# AM13E23019 register map
Vendor: Texas Instruments; File version: 1.0
CPU: CM33 r0p1, little endian, MPU, FPU, VTOR, 4 interrupt priority bits
Registers are 32-bit, read-write, reset 0x0 unless marked. A register's access mark holds for its fields unless they carry their own. Offsets are from the block's base; [hi:lo] are bit positions; {n}, {i} and the like mark numbered series; 'fields as' and 'values as' point back to an identical list.

## ADC0RESULT — ADC_RESULT module
Base 0x4000A000
Same registers: ADC1RESULT 0x4000B000, ADC2RESULT 0x4000C000
{0x0+2i} ADCRESULT{i} 16-bit access not given (i=0..15)
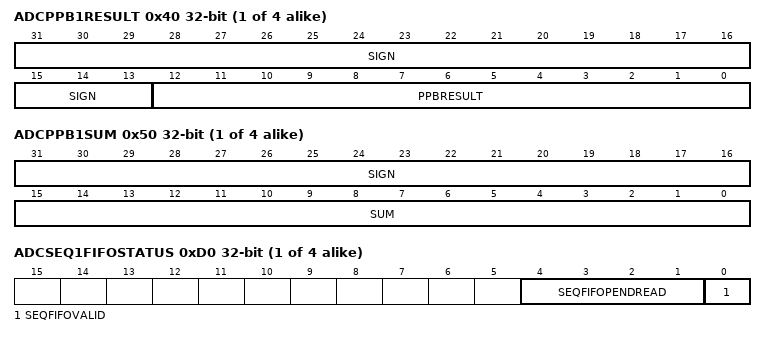
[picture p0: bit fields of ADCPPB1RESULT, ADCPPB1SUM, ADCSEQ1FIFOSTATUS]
{0x3C+4i} ADCPPB{i}RESULT ro (i=1..4) — ADC Post Processing Block {i} Result Register
  [31:13] SIGN — Sign Extended Bits
  [12:0] PPBRESULT — ADC Post Processing Block Result
{0x48+8i} ADCPPB{i}SUM ro (i=1..4) — ADC PPB {i} Final Sum Result Register
  [31:16] SIGN — Sign Extended Bits
  [15:0] SUM — Post Processing Block {i} Oversampling Sum
{0x4C+8i} ADCPPB{i}COUNT 16-bit ro (i=1..4) — ADC PPB{i} Final Conversion Count Register
  [3:0] COUNT — Post Processing Block {i} Final Count
{0xBC+4i} ADCSEQ{i}FIFORESULT access not given (i=1..4) — ADC Sequence {i} FIFO Result Register
{0xCC+4i} ADCSEQ{i}FIFOSTATUS ro (i=1..4) — ADC Sequence {i} FIFO Status
  [4:1] SEQFIFOPENDREAD — Sequencer {i} FIFO Pending reads
  [0] SEQFIFOVALID — Sequencer {i} FIFO Valid

## FRI — FRI module
Base 0x40028000
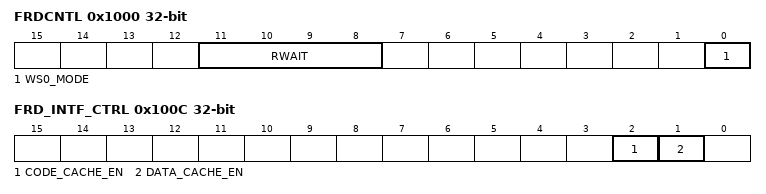
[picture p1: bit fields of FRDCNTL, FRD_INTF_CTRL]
0x1000 FRDCNTL — Flash Read Control Register
  [11:8] RWAIT — Random Read Waitstate
  [0] WS0_MODE — Wait state 0 Mode
0x100C FRD_INTF_CTRL — Flash Read Interface Control Register
  [2] CODE_CACHE_EN — Code Cache Enable
  [1] DATA_CACHE_EN — Data Cache Enable
0x1010 DTB_MUXSEL — Flash Read Interface DTB Mux select
  [1:0] DTB_MUX_SEL_FRI — FRI DTB Mux Select
0x1100 ECC_ENABLE
  [3:0] ENABLE — Enable ECC
0x1104 FECC_CTRL — ECC Control
  [1:0] ECC_TEST_EN — Enable ECC Test Logic

## MEMCFG — MEMCFG module
Base 0x4002A000
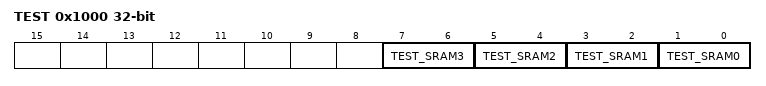
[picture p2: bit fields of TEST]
0x1000 TEST — RAM TEST Register
  [7:6] TEST_SRAM3 — Selects the different test modes for UGLXMP_2 RAM
  [5:4] TEST_SRAM2 — Selects the different test modes for GLXMP_1 RAM
  [3:2] TEST_SRAM1 — Selects the different test modes for GLXMP_0 RAM
  [1:0] TEST_SRAM0 — Selects the different test modes for ULL RAM
0x1010 ROM_WS_CONFIG — ROM wait state configuration
  [0] ROM_WS_ENABLE — ROM wait state 1 enable
0x1014 TMUROM_TEST — ROM wait state configuration
  [3:0] TMUROM_PAR_FORCE — ROM wait state 1 enable

## EAM — EAM module
Base 0x4002C000
0x1000 REVISION ro — IP revision id register
  [0] REVISION
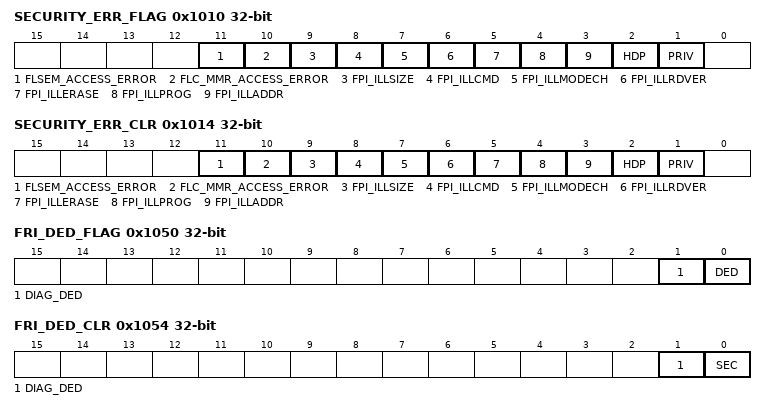
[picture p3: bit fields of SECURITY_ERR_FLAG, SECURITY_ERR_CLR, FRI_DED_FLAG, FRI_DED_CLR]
0x1010 SECURITY_ERR_FLAG ro — Security error flag
  [11] FLSEM_ACCESS_ERROR
  [10] FLC_MMR_ACCESS_ERROR
  [9] FPI_ILLSIZE
  [8] FPI_ILLCMD
  [7] FPI_ILLMODECH
  [6] FPI_ILLRDVER
  [5] FPI_ILLERASE
  [4] FPI_ILLPROG
  [3] FPI_ILLADDR
  [2] HDP — Hide protection error
  [1] PRIV — Privilege error
0x1014 SECURITY_ERR_CLR — Security error clear
  fields as SECURITY_ERR_FLAG
0x1018 SECURITY_ERR_MSTID ro — Security error master id
  [7:0] MSTID — Master ID
0x101C SECURITY_ERR_ADDR access not given — Security error address
0x1030 FRI_SEC_FLAG ro
  [0] SEC — Single error correction error
0x1034 FRI_SEC_CLR — FRI SEC clear
  [0] SEC — Single error correction error
0x1038 FRI_SEC_ADDR access not given — FRI SEC address
0x103C FRI_SEC_MSTID ro — FRI SEC master id
  [7:0] MSTID — Master ID
0x1050 FRI_DED_FLAG ro
  [1] DIAG_DED — diagnostic Double error detect error
  [0] DED — Double error detect error
0x1054 FRI_DED_CLR — FRI DED clear
  [1] DIAG_DED — diagnostic Double error detect error
  [0] SEC — Double error detect error
0x1058 FRI_DED_ADDR access not given — FRI DED address
0x105C FRI_DED_MSTID ro — FRI DED master id
  [7:0] MSTID — Master ID
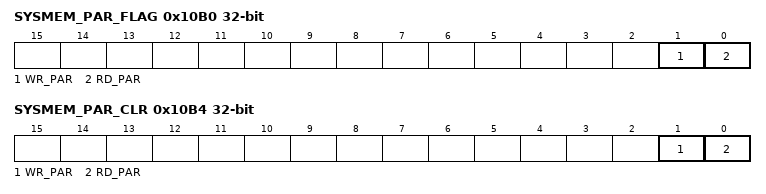
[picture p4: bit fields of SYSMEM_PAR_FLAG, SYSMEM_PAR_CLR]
0x10B0 SYSMEM_PAR_FLAG ro — SYSMEM DED flag
  [1] WR_PAR — diagnostic Double error detect error during write
  [0] RD_PAR — Double error detect error during read
0x10B4 SYSMEM_PAR_CLR — SYSMEM DED clear
  [1] WR_PAR — diagnostic Double error detect error
  [0] RD_PAR — Double error detect error
0x10B8 SYSMEM_PAR_ADDR access not given — SYSMEM DED address
0x10BC SYSMEM_PAR_MSTID ro — SYSMEM DED master id
  [7:0] MSTID — Master ID
0x10D0 TMUROM_PAR_FLAG ro — SYSMEM DED flag
  [0] PAR — Double error detect error during read
0x10D4 TMUROM_PAR_CLR — SYSMEM DED clear
  [0] PAR — Double error detect error
0x10D8 TMUROM_PAR_ADDR ro — SYSMEM DED address
  [14:0] ADDRESS
0x10DC TMUROM_PAR_TYPE ro — SYSMEM DED master id
  [2:0] TYPE — Master ID
0x10F0 SYSMEM_ACC_FLAG ro — SYSMEM access error flag
  [0] ERR
0x10F4 SYSMEM_ACC_CLR — SYSMEM access error clear
  [0] ERR — writing '1' will clear SYSMEM_ACC_FLAG[ERR] register.
0x10F8 SYSMEM_ACC_ADDR access not given — SYSMEM access error address
0x10FC SYSMEM_ACC_TYPE ro — SYSMEM access error type
  [4:0] TYPE — Access error type. This field will be cleared along with the corresponding flag clear. [4] - CBUS Access Error [3] - SBUS Access Error [2] - Write Error [1] - Read Error [0] - Fetch Error
